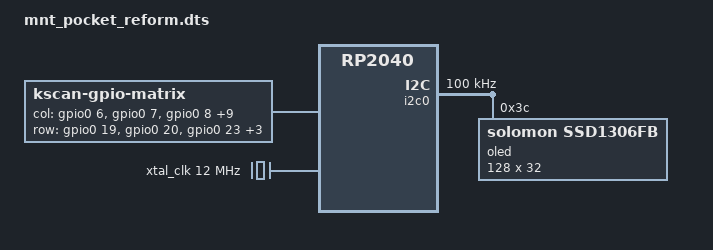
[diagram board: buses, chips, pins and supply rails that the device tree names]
/dts-v1/;

#include <rpi_pico/rp2040.dtsi>
#include "mnt_pocket_reform-pinctrl.dtsi"

/ {
    chosen {
        zephyr,display = &oled;
        zephyr,flash = &flash0;
        zephyr,sram = &sram0;
        zmk,kscan = &kscan;
    };

    kscan: kscan {
        compatible = "zmk,kscan-gpio-matrix";
        col-gpios
            = <&gpio0  6 (GPIO_ACTIVE_HIGH)>
            , <&gpio0  7 (GPIO_ACTIVE_HIGH)>
            , <&gpio0  8 (GPIO_ACTIVE_HIGH)>
            , <&gpio0  9 (GPIO_ACTIVE_HIGH)>
            , <&gpio0 10 (GPIO_ACTIVE_HIGH)>
            , <&gpio0 11 (GPIO_ACTIVE_HIGH)>
            , <&gpio0 12 (GPIO_ACTIVE_HIGH)>
            , <&gpio0 13 (GPIO_ACTIVE_HIGH)>
            , <&gpio0 14 (GPIO_ACTIVE_HIGH)>
            , <&gpio0 15 (GPIO_ACTIVE_HIGH)>
            , <&gpio0 16 (GPIO_ACTIVE_HIGH)>
            , <&gpio0 17 (GPIO_ACTIVE_HIGH)>
            ;
        row-gpios
            = <&gpio0 19 (GPIO_ACTIVE_HIGH | GPIO_PULL_DOWN)>
            , <&gpio0 20 (GPIO_ACTIVE_HIGH | GPIO_PULL_DOWN)>
            , <&gpio0 23 (GPIO_ACTIVE_HIGH | GPIO_PULL_DOWN)>
            , <&gpio0 22 (GPIO_ACTIVE_HIGH | GPIO_PULL_DOWN)>
            , <&gpio0 21 (GPIO_ACTIVE_HIGH | GPIO_PULL_DOWN)>
            , <&gpio0 18 (GPIO_ACTIVE_HIGH | GPIO_PULL_DOWN)>
            ;
    };

    xtal_clk: xtal-clk {
        compatible = "fixed-clock";
        clock-frequency = <12000000>;
        #clock-cells = <0>;
    };
};

&flash0 {
    // W25Q32JVSS
    reg = <0x10000000 DT_SIZE_M(4)>;
};

&gpio0 {
    status = "okay";
};

&i2c0 {
    status = "okay";
    clock-frequency = <I2C_BITRATE_STANDARD>;
    pinctrl-0 = <&i2c0_default>;
    pinctrl-names = "default";

    oled: ssd1306@3c {
        compatible = "solomon,ssd1306fb";
        reg = <0x3c>;
        width = <128>;
        height = <32>;
        segment-offset = <0>;
        page-offset = <0>;
        display-offset = <0>;
        multiplex-ratio = <31>;
        prechargep = <0x22>;
    };
};
